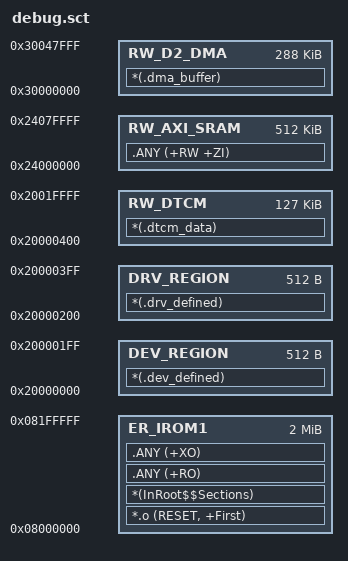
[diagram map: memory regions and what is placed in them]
; STM32H743 Scatter File
; DTCM     : FOC 控制核心与高实时数据
; D2 SRAM  : DMA 缓冲区
; AXI SRAM : 普通全局变量与大块缓冲

LR_IROM1 0x08000000 0x00200000  {
  ER_IROM1 0x08000000 0x00200000  {
   *.o (RESET, +First)
   *(InRoot$$Sections)
   .ANY (+RO)
   .ANY (+XO)
  }

  ; --- DTCM (0x2000_0000, 128KB) ---
  DEV_REGION 0x20000000 0x00000200  {
   *(.dev_defined)
  }

  DRV_REGION 0x20000200 0x00000200  {
   *(.drv_defined)
  }

  RW_DTCM 0x20000400 0x0001FC00  {
   *(.dtcm_data)
  }

  ; --- D2 SRAM (0x3000_0000, 288KB) ---
  RW_D2_DMA 0x30000000 0x00048000  {
   *(.dma_buffer)
  }

  ; --- AXI SRAM (0x2400_0000, 512KB) ---
  RW_AXI_SRAM 0x24000000 0x00080000  {
   .ANY (+RW +ZI)
  }
}
